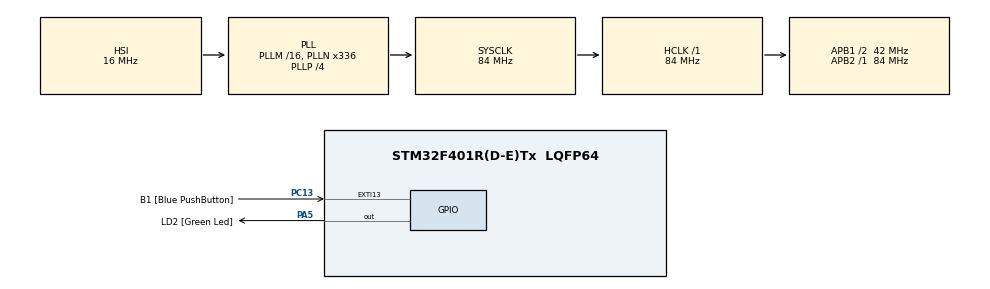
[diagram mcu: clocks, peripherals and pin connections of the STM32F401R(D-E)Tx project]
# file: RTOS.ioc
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Mcu.Family=STM32F4
PC15-OSC32_OUT.Mode=LSE-External-Oscillator
RCC.CortexFreq_Value=84000000
FREERTOS.Tasks01=defaultTask,0,128,StartDefaultTask,Default,NULL,Dynamic,NULL,NULL
PC13-ANTI_TAMP.GPIO_PuPd=GPIO_NOPULL
PC13-ANTI_TAMP.GPIO_Label=B1 [Blue PushButton]
PA14.GPIO_Label=TCK
PH1\ -\ OSC_OUT.Mode=HSE-External-Clock-Source
RCC.APB1CLKDivider=RCC_HCLK_DIV2
PC14-OSC32_IN.Signal=RCC_OSC32_IN
RCC.SYSCLKSource=RCC_SYSCLKSOURCE_PLLCLK
ProjectManager.StackSize=0x400
PA13.Signal=SYS_JTMS-SWDIO
PH0\ -\ OSC_IN.Mode=HSE-External-Clock-Source
PH0\ -\ OSC_IN.Signal=RCC_OSC_IN
ProjectManager.TargetToolchain=Makefile
RCC.HCLKFreq_Value=84000000
RCC.APB2TimFreq_Value=84000000
PC15-OSC32_OUT.Signal=RCC_OSC32_OUT
RCC.AHBFreq_Value=84000000
PA5.Signal=GPIO_Output
RCC.HSE_VALUE=8000000
PH1\ -\ OSC_OUT.Signal=RCC_OSC_OUT
board=NUCLEO-F401RE
PC13-ANTI_TAMP.Signal=GPXTI13
RCC.VCOOutputFreq_Value=336000000
RCC.APB2Freq_Value=84000000
PC14-OSC32_IN.Mode=LSE-External-Oscillator
PA14.Mode=Serial_Wire
VP_SYS_VS_tim1.Mode=TIM1
PA5.GPIO_PuPd=GPIO_NOPULL
VP_FREERTOS_VS_CMSIS_V1.Mode=CMSIS_V1
PA13.Mode=Serial_Wire
Mcu.Name=STM32F401R(D-E)Tx
PA13.GPIO_Label=TMS
RCC.48MHZClocksFreq_Value=48000000
RCC.SYSCLKFreq_VALUE=84000000
Mcu.Package=LQFP64
NVIC.TimeBase=TIM1_UP_TIM10_IRQn
PA5.GPIO_Label=LD2 [Green Led]
PC13-ANTI_TAMP.GPIO_ModeDefaultEXTI=GPIO_MODE_IT_FALLING
NVIC.TimeBaseIP=TIM1
PA14.Signal=SYS_JTCK-SWCLK
ProjectManager.HeapSize=0x200
NVIC.TIM1_UP_TIM10_IRQn=true\:0\:0\:false\:false\:true\:false\:false\:true
RCC.HSI_VALUE=16000000
RCC.PLLP=RCC_PLLP_DIV4
PA5.GPIO_Speed=GPIO_SPEED_FREQ_LOW
RCC.PLLQ=7
NVIC.PriorityGroup=NVIC_PRIORITYGROUP_4
RCC.PLLN=336
RCC.APB1TimFreq_Value=84000000
RCC.APB1Freq_Value=42000000
PA5.GPIO_Mode=GPIO_MODE_OUTPUT_PP

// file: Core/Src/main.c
/* USER CODE BEGIN Header */
/**
  ******************************************************************************
  * @file           : main.c
  * @brief          : Main program body
  ******************************************************************************
  * @attention
  *
  * <h2><center>&copy; Copyright (c) 2021 STMicroelectronics.
  * All rights reserved.</center></h2>
  *
  * This software component is licensed by ST under Ultimate Liberty license
  * SLA0044, the "License"; You may not use this file except in compliance with
  * the License. You may obtain a copy of the License at:
  *                             www.st.com/SLA0044
  *
  ******************************************************************************
  */
/* USER CODE END Header */
#include "main.h"
#include "cmsis_os.h"
#include "gpio.h"

void SystemClock_Config(void);
void MX_FREERTOS_Init(void);

int main(void)
{

  /* MCU Configuration--------------------------------------------------------*/

  /* Reset of all peripherals, Initializes the Flash interface and the Systick. */
  HAL_Init();

  /* Configure the system clock */
  SystemClock_Config();

  /* Initialize all configured peripherals */
  MX_GPIO_Init();

  /* Call init function for freertos objects (in freertos.c) */
  MX_FREERTOS_Init();
  /* Start scheduler */
  osKernelStart();

  /* We should never get here as control is now taken by the scheduler */
  /* Infinite loop */
  while (1)
  {

  }
}

void SystemClock_Config(void)
{
  RCC_OscInitTypeDef RCC_OscInitStruct = {0};
  RCC_ClkInitTypeDef RCC_ClkInitStruct = {0};

  /** Configure the main internal regulator output voltage
  */
  __HAL_RCC_PWR_CLK_ENABLE();
  __HAL_PWR_VOLTAGESCALING_CONFIG(PWR_REGULATOR_VOLTAGE_SCALE2);
  /** Initializes the RCC Oscillators according to the specified parameters
  * in the RCC_OscInitTypeDef structure.
  */
  RCC_OscInitStruct.OscillatorType = RCC_OSCILLATORTYPE_HSI;
  RCC_OscInitStruct.HSIState = RCC_HSI_ON;
  RCC_OscInitStruct.HSICalibrationValue = RCC_HSICALIBRATION_DEFAULT;
  RCC_OscInitStruct.PLL.PLLState = RCC_PLL_ON;
  RCC_OscInitStruct.PLL.PLLSource = RCC_PLLSOURCE_HSI;
  RCC_OscInitStruct.PLL.PLLM = 16;
  RCC_OscInitStruct.PLL.PLLN = 336;
  RCC_OscInitStruct.PLL.PLLP = RCC_PLLP_DIV4;
  RCC_OscInitStruct.PLL.PLLQ = 7;
  if (HAL_RCC_OscConfig(&RCC_OscInitStruct) != HAL_OK)
  {
    Error_Handler();
  }
  /** Initializes the CPU, AHB and APB buses clocks
  */
  RCC_ClkInitStruct.ClockType = RCC_CLOCKTYPE_HCLK|RCC_CLOCKTYPE_SYSCLK
                              |RCC_CLOCKTYPE_PCLK1|RCC_CLOCKTYPE_PCLK2;
  RCC_ClkInitStruct.SYSCLKSource = RCC_SYSCLKSOURCE_PLLCLK;
  RCC_ClkInitStruct.AHBCLKDivider = RCC_SYSCLK_DIV1;
  RCC_ClkInitStruct.APB1CLKDivider = RCC_HCLK_DIV2;
  RCC_ClkInitStruct.APB2CLKDivider = RCC_HCLK_DIV1;

  if (HAL_RCC_ClockConfig(&RCC_ClkInitStruct, FLASH_LATENCY_2) != HAL_OK)
  {
    Error_Handler();
  }
}

void HAL_TIM_PeriodElapsedCallback(TIM_HandleTypeDef *htim)
{
  if (htim->Instance == TIM1) {
    HAL_IncTick();
  }
}

void Error_Handler(void)
{
}

/************************ (C) COPYRIGHT STMicroelectronics *****END OF FILE****/

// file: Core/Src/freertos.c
/* USER CODE BEGIN Header */
/**
  ******************************************************************************
  * File Name          : freertos.c
  * Description        : Code for freertos applications
  ******************************************************************************
  * @attention
  *
  * <h2><center>&copy; Copyright (c) 2021 STMicroelectronics.
  * All rights reserved.</center></h2>
  *
  * This software component is licensed by ST under Ultimate Liberty license
  * SLA0044, the "License"; You may not use this file except in compliance with
  * the License. You may obtain a copy of the License at:
  *                             www.st.com/SLA0044
  *
  ******************************************************************************
  */
/* USER CODE END Header */

#include "FreeRTOS.h"
#include "task.h"
#include "main.h"
#include "cmsis_os.h"

#include "gpio.h"

osThreadId defaultTaskHandle;
osThreadId LEDTaskHandle;

void StartDefaultTask(void const * argument);
void StartLEDTask(void const * argument);

void MX_FREERTOS_Init(void); /* (MISRA C 2004 rule 8.1) */

/* GetIdleTaskMemory prototype (linked to static allocation support) */
void vApplicationGetIdleTaskMemory( StaticTask_t **ppxIdleTaskTCBBuffer, StackType_t **ppxIdleTaskStackBuffer, uint32_t *pulIdleTaskStackSize );

/* USER CODE BEGIN GET_IDLE_TASK_MEMORY */
static StaticTask_t xIdleTaskTCBBuffer;
static StackType_t xIdleStack[configMINIMAL_STACK_SIZE];

void vApplicationGetIdleTaskMemory( StaticTask_t **ppxIdleTaskTCBBuffer, StackType_t **ppxIdleTaskStackBuffer, uint32_t *pulIdleTaskStackSize )
{
  *ppxIdleTaskTCBBuffer = &xIdleTaskTCBBuffer;
  *ppxIdleTaskStackBuffer = &xIdleStack[0];
  *pulIdleTaskStackSize = configMINIMAL_STACK_SIZE;
  /* place for user code */
}
/* USER CODE END GET_IDLE_TASK_MEMORY */

void MX_FREERTOS_Init(void) {

  /* Create the thread(s) */
  /* definition and creation of defaultTask */
  osThreadDef(defaultTask, StartDefaultTask, osPriorityNormal, 0, 128);
  defaultTaskHandle = osThreadCreate(osThread(defaultTask), NULL);

  osThreadDef(LEDTask, StartLEDTask, osPriorityNormal, 0, 128);
  LEDTaskHandle = osThreadCreate(osThread(LEDTask), NULL);

}

void StartDefaultTask(void const * argument)
{
  /* USER CODE BEGIN StartDefaultTask */
  /* Infinite loop */
  for(;;)
  {
    osDelay(100);
  }
  /* USER CODE END StartDefaultTask */
}

void StartLEDTask(void const * argument)
{
  /* USER CODE BEGIN StartDefaultTask */
  /* Infinite loop */
  for(;;)
  {
    osDelay(100);
    HAL_GPIO_TogglePin(GPIOA, GPIO_PIN_5);
  }
  /* USER CODE END StartDefaultTask */
}

/************************ (C) COPYRIGHT STMicroelectronics *****END OF FILE****/
